# PIC32CZ2038CA70144 device description
Architecture: CORTEX-M7; Family: PIC32CZ; Series: CA70
Registers are 32-bit, read-write, no defined reset value unless marked. A register's access mark holds for its fields unless they carry their own. Offsets are from the block's base; [hi:lo] are bit positions; {n}, {i} and the like mark numbered series.

## PORT
Instances: PORTA 0x400E0E00, PORTB 0x400E1000, PORTC 0x400E1200, PORTD 0x400E1400, PORTE 0x400E1600
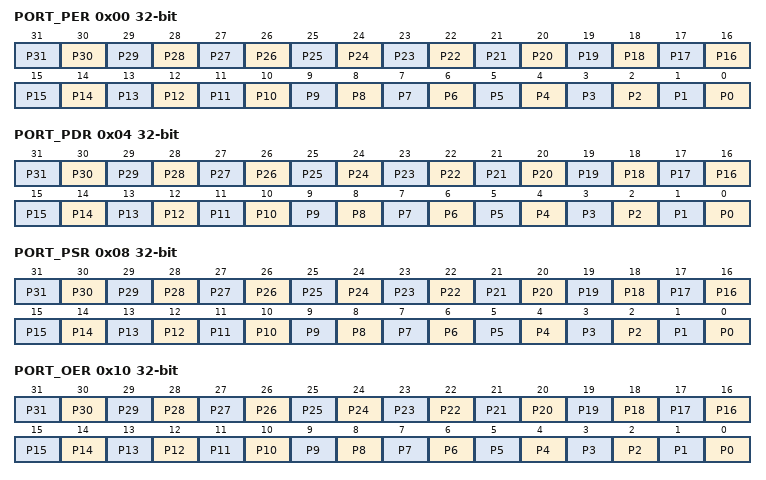
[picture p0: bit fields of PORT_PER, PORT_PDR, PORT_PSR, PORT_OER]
0x00 PORT_PER wo (atomic set of PORT_PSR) — PORT Enable Register
  [n] P{n} (n=0..31) — PORT Enable
0x04 PORT_PDR wo (atomic clear of PORT_PSR) — PORT Disable Register
  [n] P{n} (n=0..31) — PORT Disable
0x08 PORT_PSR ro — PORT Status Register
  [n] P{n} (n=0..31) — PORT Status
0x10 PORT_OER wo (atomic set of PORT_OSR) — Output Enable Register
  [n] P{n} (n=0..31) — Output Enable
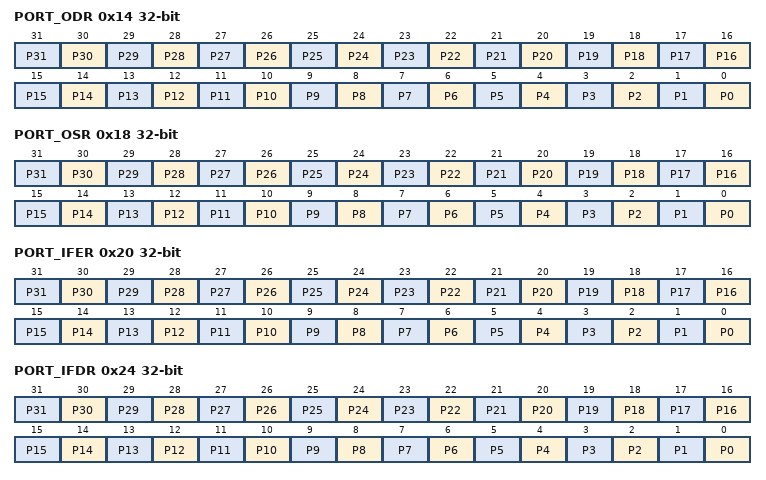
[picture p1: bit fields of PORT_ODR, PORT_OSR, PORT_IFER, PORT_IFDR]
0x14 PORT_ODR wo (atomic clear of PORT_OSR) — Output Disable Register
  [n] P{n} (n=0..31) — Output Disable
0x18 PORT_OSR ro — Output Status Register
  [n] P{n} (n=0..31) — Output Status
0x20 PORT_IFER wo (atomic set of PORT_IFSR) — Glitch Input Filter Enable Register
  [n] P{n} (n=0..31) — Input Filter Enable
0x24 PORT_IFDR wo (atomic clear of PORT_IFSR) — Glitch Input Filter Disable Register
  [n] P{n} (n=0..31) — Input Filter Disable
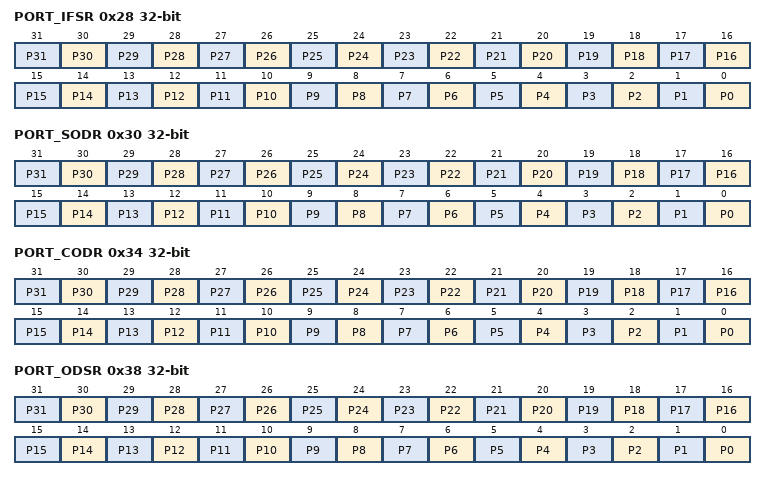
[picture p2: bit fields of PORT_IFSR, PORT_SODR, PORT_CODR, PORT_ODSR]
0x28 PORT_IFSR ro — Glitch Input Filter Status Register
  [n] P{n} (n=0..31) — Input Filter Status
0x30 PORT_SODR wo (atomic set of PORT_ODSR) — Set Output Data Register
  [n] P{n} (n=0..31) — Set Output Data
0x34 PORT_CODR wo (atomic clear of PORT_ODSR) — Clear Output Data Register
  [n] P{n} (n=0..31) — Clear Output Data
0x38 PORT_ODSR — Output Data Status Register
  [n] P{n} (n=0..31) — Output Data Status
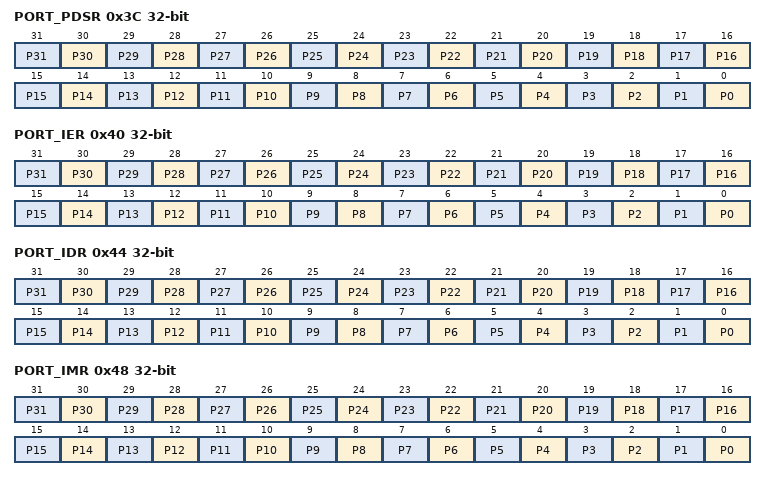
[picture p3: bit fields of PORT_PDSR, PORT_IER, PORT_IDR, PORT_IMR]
0x3C PORT_PDSR ro — Pin Data Status Register
  [n] P{n} (n=0..31) — Output Data Status
0x40 PORT_IER wo (atomic set of PORT_IMR) — Interrupt Enable Register
  [n] P{n} (n=0..31) — Input Change Interrupt Enable
0x44 PORT_IDR wo (atomic clear of PORT_IMR) — Interrupt Disable Register
  [n] P{n} (n=0..31) — Input Change Interrupt Disable
0x48 PORT_IMR ro (atomic read) — Interrupt Mask Register
  [n] P{n} (n=0..31) — Input Change Interrupt Mask
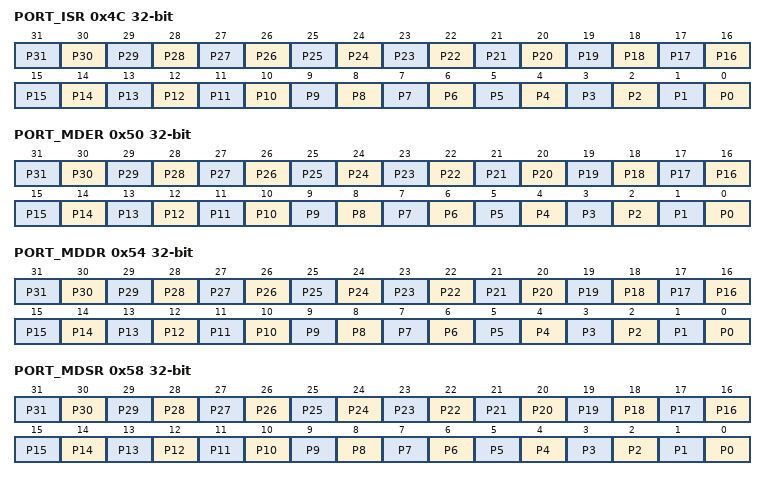
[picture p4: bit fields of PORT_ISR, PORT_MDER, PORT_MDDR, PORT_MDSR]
0x4C PORT_ISR ro (atomic clear) — Interrupt Status Register
  [n] P{n} (n=0..31) — Input Change Interrupt Status
0x50 PORT_MDER wo (atomic set of PORT_MDSR) — Multi-driver Enable Register
  [n] P{n} (n=0..31) — Multi-drive Enable
0x54 PORT_MDDR wo (atomic clear of PORT_MDSR) — Multi-driver Disable Register
  [n] P{n} (n=0..31) — Multi-drive Disable
0x58 PORT_MDSR ro — Multi-driver Status Register
  [n] P{n} (n=0..31) — Multi-drive Status
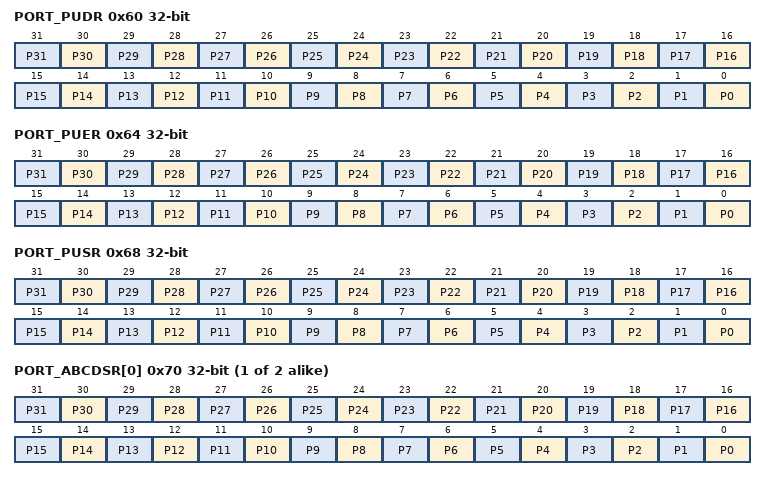
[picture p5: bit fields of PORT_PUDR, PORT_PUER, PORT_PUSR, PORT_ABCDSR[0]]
0x60 PORT_PUDR wo (atomic clear of PORT_PUSR) — Pull-up Disable Register
  [n] P{n} (n=0..31) — Pull-Up Disable
0x64 PORT_PUER wo (atomic set of PORT_PUSR) — Pull-up Enable Register
  [n] P{n} (n=0..31) — Pull-Up Enable
0x68 PORT_PUSR ro — Pad Pull-up Status Register
  [n] P{n} (n=0..31) — Pull-Up Status
{0x70+4i} PORT_ABCDSR[{i}] (i=0..1) — Peripheral ABCD Select Register 0
  [n] P{n} (n=0..31) — Peripheral Select
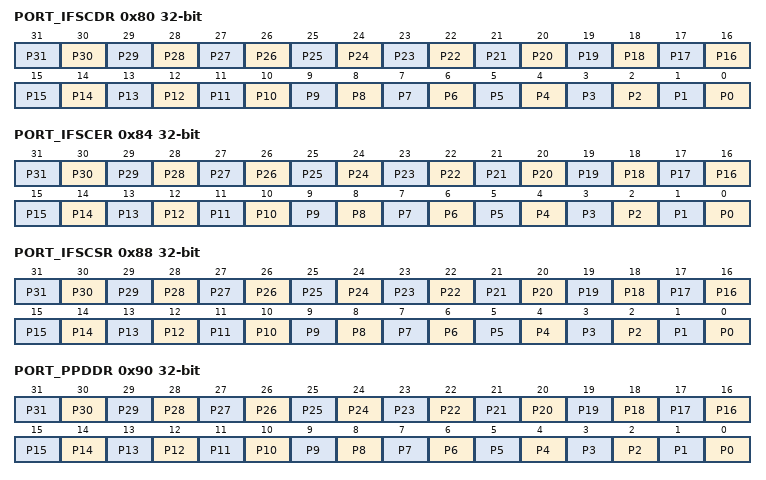
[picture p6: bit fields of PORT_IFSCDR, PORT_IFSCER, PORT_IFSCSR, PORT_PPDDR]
0x80 PORT_IFSCDR wo (atomic clear of PORT_IFSCSR) — Input Filter Slow Clock Disable Register
  [n] P{n} (n=0..31) — Peripheral Clock Glitch Filtering Select
0x84 PORT_IFSCER wo (atomic set of PORT_IFSCSR) — Input Filter Slow Clock Enable Register
  [n] P{n} (n=0..31) — Slow Clock Debouncing Filtering Select
0x88 PORT_IFSCSR ro — Input Filter Slow Clock Status Register
  [n] P{n} (n=0..31) — Glitch or Debouncing Filter Selection Status
0x8C PORT_SCDR — Slow Clock Divider Debouncing Register
  [13:0] DIV — Slow Clock Divider Selection for Debouncing
0x90 PORT_PPDDR wo (atomic clear of PORT_PPDSR) — Pad Pull-down Disable Register
  [n] P{n} (n=0..31) — Pull-Down Disable
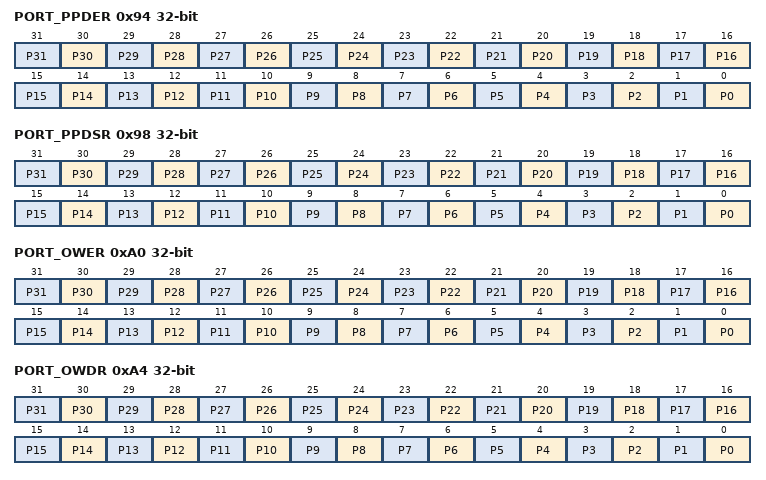
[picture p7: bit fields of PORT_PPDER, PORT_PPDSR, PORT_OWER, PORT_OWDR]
0x94 PORT_PPDER wo (atomic set of PORT_PPDSR) — Pad Pull-down Enable Register
  [n] P{n} (n=0..31) — Pull-Down Enable
0x98 PORT_PPDSR ro — Pad Pull-down Status Register
  [n] P{n} (n=0..31) — Pull-Down Status
0xA0 PORT_OWER wo (atomic set of PORT_OWSR) — Output Write Enable
  [n] P{n} (n=0..31) — Output Write Enable
0xA4 PORT_OWDR wo (atomic clear of PORT_OWSR) — Output Write Disable
  [n] P{n} (n=0..31) — Output Write Disable
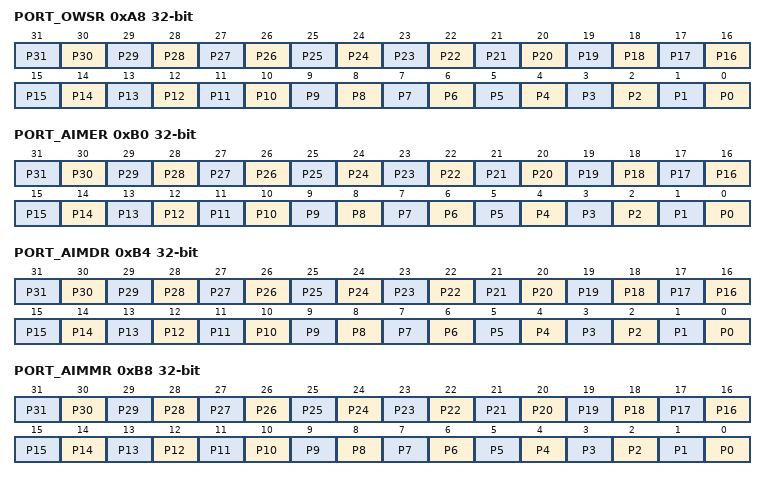
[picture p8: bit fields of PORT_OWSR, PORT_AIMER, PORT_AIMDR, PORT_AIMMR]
0xA8 PORT_OWSR ro — Output Write Status Register
  [n] P{n} (n=0..31) — Output Write Status
0xB0 PORT_AIMER wo (atomic set of PORT_AIMMR) — Additional Interrupt Modes Enable Register
  [n] P{n} (n=0..31) — Additional Interrupt Modes Enable
0xB4 PORT_AIMDR wo (atomic clear of PORT_AIMMR) — Additional Interrupt Modes Disable Register
  [n] P{n} (n=0..31) — Additional Interrupt Modes Disable
0xB8 PORT_AIMMR ro — Additional Interrupt Modes Mask Register
  [n] P{n} (n=0..31) — IO Line Index
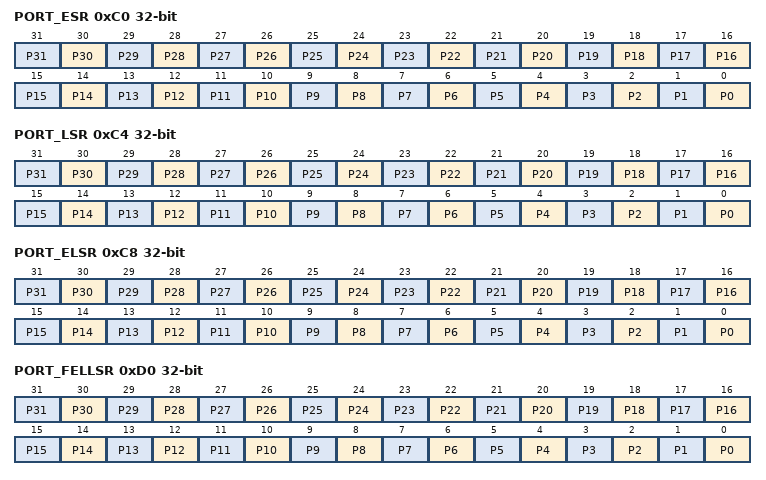
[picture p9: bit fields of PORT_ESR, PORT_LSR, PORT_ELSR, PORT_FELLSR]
0xC0 PORT_ESR wo (atomic clear of PORT_ELSR) — Edge Select Register
  [n] P{n} (n=0..31) — Edge Interrupt Selection
0xC4 PORT_LSR wo (atomic set of PORT_ELSR) — Level Select Register
  [n] P{n} (n=0..31) — Level Interrupt Selection
0xC8 PORT_ELSR ro — Edge/Level Status Register
  [n] P{n} (n=0..31) — Edge/Level Interrupt Source Selection
0xD0 PORT_FELLSR wo (atomic clear of PORT_FRLHSR) — Falling Edge/Low-Level Select Register
  [n] P{n} (n=0..31) — Falling Edge/Low-Level Interrupt Selection
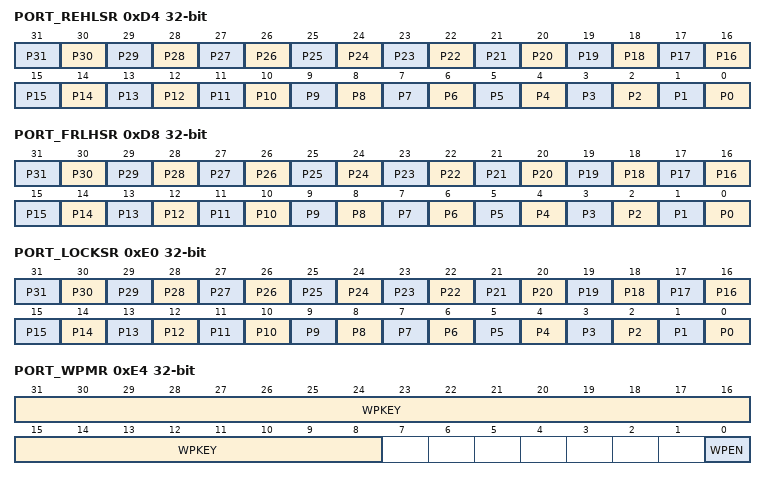
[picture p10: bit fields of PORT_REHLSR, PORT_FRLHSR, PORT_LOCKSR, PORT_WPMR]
0xD4 PORT_REHLSR wo (atomic set of PORT_FRLHSR) — Rising Edge/High-Level Select Register
  [n] P{n} (n=0..31) — Rising Edge/High-Level Interrupt Selection
0xD8 PORT_FRLHSR ro — Fall/Rise - Low/High Status Register
  [n] P{n} (n=0..31) — Edge/Level Interrupt Source Selection
0xE0 PORT_LOCKSR ro — Lock Status
  [n] P{n} (n=0..31) — Lock Status
0xE4 PORT_WPMR — Write Protection Mode Register
  [31:8] WPKEY — Write Protection Key
    0x50494F=PASSWD (Writing any other value in this field aborts the write operation of the WPEN bit.Always reads as 0.)
  [0] WPEN — Write Protection Enable
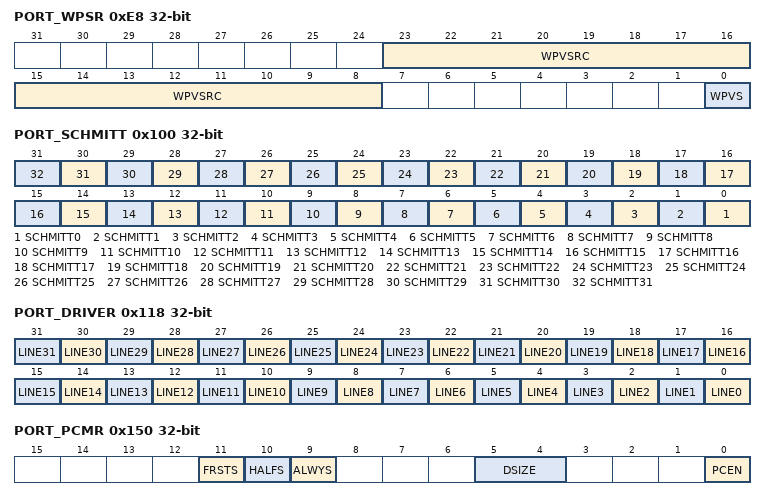
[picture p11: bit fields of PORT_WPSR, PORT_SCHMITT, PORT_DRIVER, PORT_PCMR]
0xE8 PORT_WPSR ro — Write Protection Status Register
  [23:8] WPVSRC — Write Protection Violation Source
  [0] WPVS — Write Protection Violation Status
0x100 PORT_SCHMITT — Schmitt Trigger Register
  [n] SCHMITT{n} (n=0..31) — Schmitt Trigger Control
0x118 PORT_DRIVER — I/O Drive Register
  [all] fields
    0=LOW_DRIVE (Lowest drive); 1=HIGH_DRIVE (Highest drive)
  [n] LINE{n} (n=0..31) — Drive of PORT Line {n}
0x150 PORT_PCMR — Parallel Capture Mode Register
  [11] FRSTS — Parallel Capture Mode First Sample
  [10] HALFS — Parallel Capture Mode Half Sampling
  [9] ALWYS — Parallel Capture Mode Always Sampling
  [5:4] DSIZE — Parallel Capture Mode Data Size
    0=BYTE (The reception data in the PORT_PCRHR is a byte (8-bit)); 1=HALFWORD (The reception data in the PORT_PCRHR is a half-word (16-bit)); 2=WORD (The reception data in the PORT_PCRHR is a word (32-bit))
  [0] PCEN — Parallel Capture Mode Enable
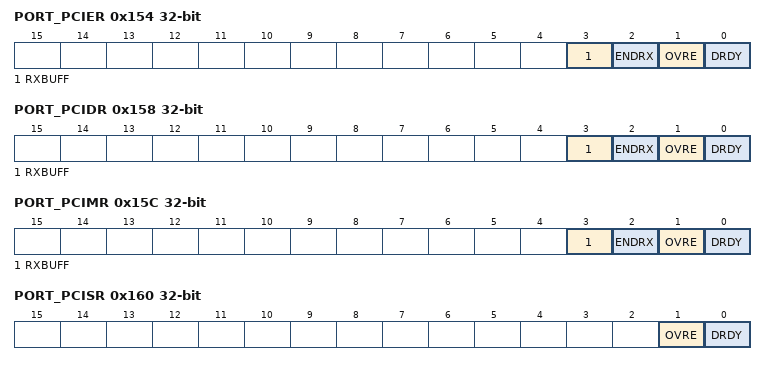
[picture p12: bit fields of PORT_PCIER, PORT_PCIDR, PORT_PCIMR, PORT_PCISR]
0x154 PORT_PCIER wo — Parallel Capture Interrupt Enable Register
  [3] RXBUFF — Reception Buffer Full Interrupt Enable
  [2] ENDRX — End of Reception Transfer Interrupt Enable
  [1] OVRE — Parallel Capture Mode Overrun Error Interrupt Enable
  [0] DRDY — Parallel Capture Mode Data Ready Interrupt Enable
0x158 PORT_PCIDR wo — Parallel Capture Interrupt Disable Register
  [3] RXBUFF — Reception Buffer Full Interrupt Disable
  [2] ENDRX — End of Reception Transfer Interrupt Disable
  [1] OVRE — Parallel Capture Mode Overrun Error Interrupt Disable
  [0] DRDY — Parallel Capture Mode Data Ready Interrupt Disable
0x15C PORT_PCIMR ro — Parallel Capture Interrupt Mask Register
  [3] RXBUFF — Reception Buffer Full Interrupt Mask
  [2] ENDRX — End of Reception Transfer Interrupt Mask
  [1] OVRE — Parallel Capture Mode Overrun Error Interrupt Mask
  [0] DRDY — Parallel Capture Mode Data Ready Interrupt Mask
0x160 PORT_PCISR ro — Parallel Capture Interrupt Status Register
  [1] OVRE — Parallel Capture Mode Overrun Error
  [0] DRDY — Parallel Capture Mode Data Ready
0x164 PORT_PCRHR ro — Parallel Capture Reception Holding Register
  [31:0] RDATA — Parallel Capture Mode Reception Data
